# gcfr_me18 register map
Registers are read-write, no defined reset value unless marked. A register's access mark holds for its fields unless they carry their own. Offsets are from the block's base; lines under a group give offsets from that group; [hi:lo] are bit positions; {n}, {i} and the like mark numbered series; 'fields as' and 'values as' point back to an identical list; <NAME> marks a mode.

## Memory map
0x40005800 GCFR size 0x400 — Global Control Function Register.

## GCFR — Global Control Function Register.
Base 0x40005800
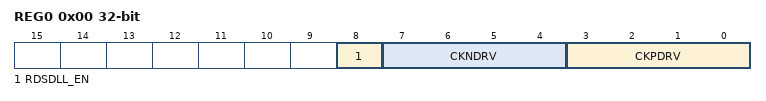
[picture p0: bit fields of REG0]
0x00 REG0 — Register 0.
  [8] RDSDLL_EN — Hyperbus RDS DLL Enable.
  [7:4] CKNDRV — Hyperbus CKN Drive Setting.
  [3:0] CKPDRV — Hyperbus CKP Drive Setting.
